# PIC32MK0512GPL100 register map
Vendor: Microchip
Registers are 32-bit, read-write, no defined reset value unless marked. A register's access mark holds for its fields unless they carry their own. Addresses are absolute, and some are shared; only a register's first bit layout is shown; [hi:lo] are bit positions; {n}, {i} and the like mark numbered series.

## PORTB
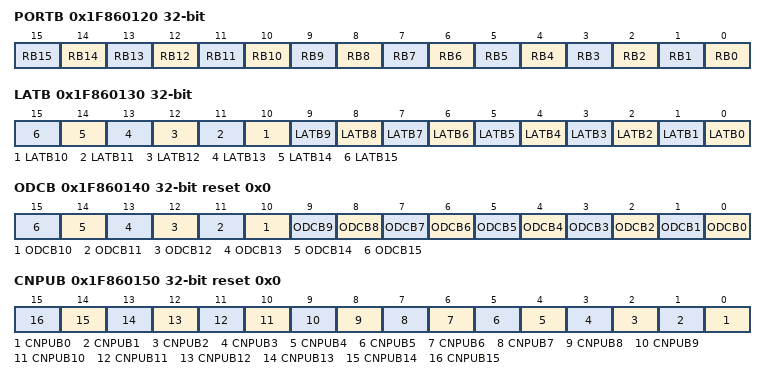
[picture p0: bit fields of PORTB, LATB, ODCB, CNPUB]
0x1F860120 PORTB — (power-on value ----------------xxxxxxxxxxxxxxxx)
  [n] RB{n} (n=0..15)
0x1F860130 LATB — (power-on value ----------------xxxxxxxxxxxxxxxx)
  [n] LATB{n} (n=0..15)
0x1F860140 ODCB reset 0x0
  [n] ODCB{n} (n=0..15)
0x1F860150 CNPUB reset 0x0
  [n] CNPUB{n} (n=0..15)
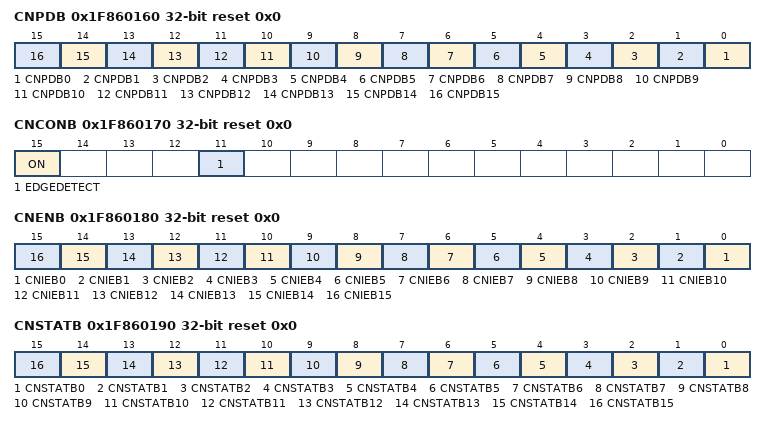
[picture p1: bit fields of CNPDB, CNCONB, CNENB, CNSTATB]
0x1F860160 CNPDB reset 0x0
  [n] CNPDB{n} (n=0..15)
0x1F860170 CNCONB reset 0x0
  [15] ON, [11] EDGEDETECT
0x1F860180 CNENB reset 0x0
  [n] CNIEB{n} (n=0..15)
0x1F860190 CNSTATB reset 0x0
  [n] CNSTATB{n} (n=0..15)
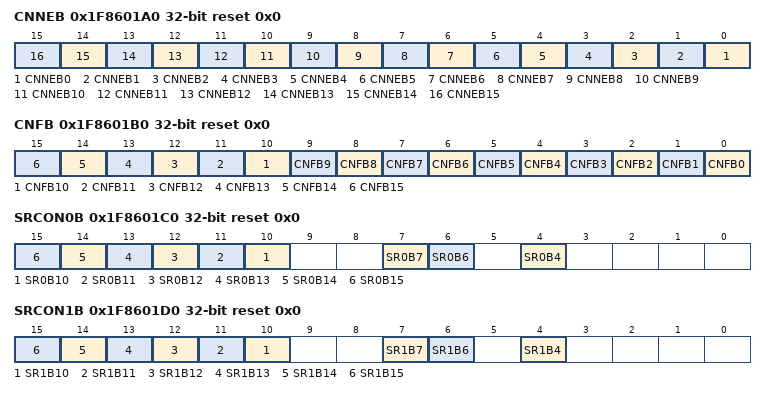
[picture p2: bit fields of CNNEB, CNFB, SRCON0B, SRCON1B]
0x1F8601A0 CNNEB reset 0x0
  [n] CNNEB{n} (n=0..15)
0x1F8601B0 CNFB reset 0x0
  [n] CNFB{n} (n=0..15)
0x1F8601C0 SRCON0B reset 0x0
  [n] SR0B{n} (n=10..15), [7] SR0B7, [6] SR0B6, [4] SR0B4
0x1F8601D0 SRCON1B reset 0x0
  [n] SR1B{n} (n=10..15), [7] SR1B7, [6] SR1B6, [4] SR1B4

## PORTC
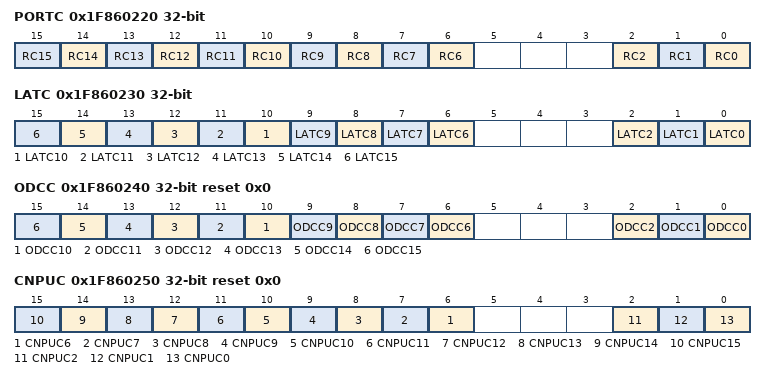
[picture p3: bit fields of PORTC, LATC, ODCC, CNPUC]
0x1F860220 PORTC — (power-on value ----------------xxxxxxxxxx---xxx)
  [n] RC{n} (n=6..15), [2] RC2, [1] RC1, [0] RC0
0x1F860230 LATC — (power-on value ----------------xxxxxxxxxx---xxx)
  [n] LATC{n} (n=6..15), [2] LATC2, [1] LATC1, [0] LATC0
0x1F860240 ODCC reset 0x0
  [n] ODCC{n} (n=6..15), [2] ODCC2, [1] ODCC1, [0] ODCC0
0x1F860250 CNPUC reset 0x0
  [n] CNPUC{n} (n=6..15), [2] CNPUC2, [1] CNPUC1, [0] CNPUC0
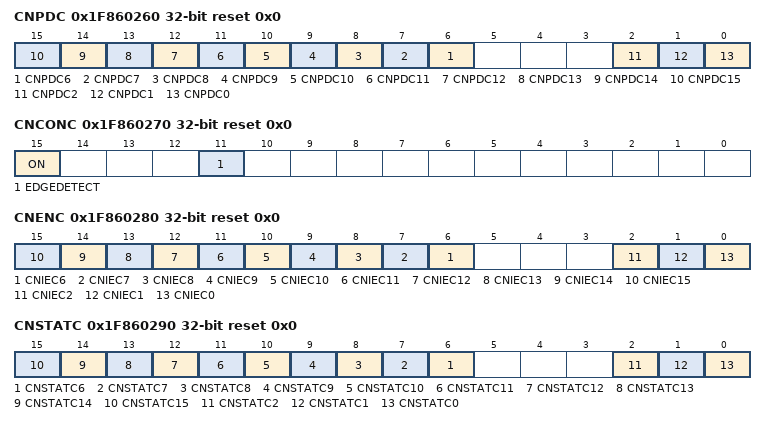
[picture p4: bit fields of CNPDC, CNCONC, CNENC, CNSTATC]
0x1F860260 CNPDC reset 0x0
  [n] CNPDC{n} (n=6..15), [2] CNPDC2, [1] CNPDC1, [0] CNPDC0
0x1F860270 CNCONC reset 0x0
  [15] ON, [11] EDGEDETECT
0x1F860280 CNENC reset 0x0
  [n] CNIEC{n} (n=6..15), [2] CNIEC2, [1] CNIEC1, [0] CNIEC0
0x1F860290 CNSTATC reset 0x0
  [n] CNSTATC{n} (n=6..15), [2] CNSTATC2, [1] CNSTATC1, [0] CNSTATC0
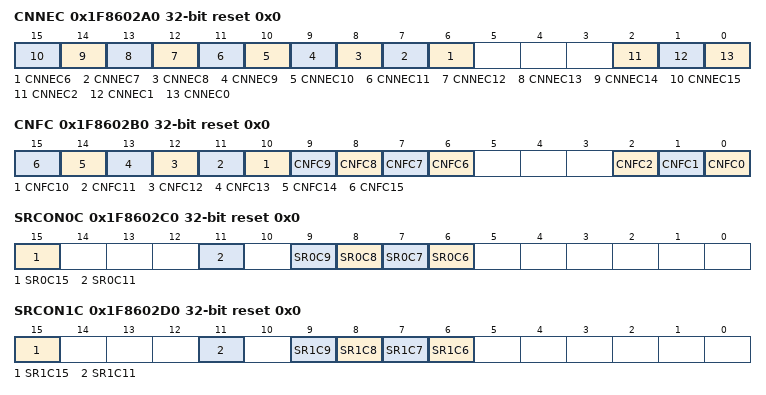
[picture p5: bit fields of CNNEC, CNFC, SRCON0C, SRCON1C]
0x1F8602A0 CNNEC reset 0x0
  [n] CNNEC{n} (n=6..15), [2] CNNEC2, [1] CNNEC1, [0] CNNEC0
0x1F8602B0 CNFC reset 0x0
  [n] CNFC{n} (n=6..15), [2] CNFC2, [1] CNFC1, [0] CNFC0
0x1F8602C0 SRCON0C reset 0x0
  [15] SR0C15, [11] SR0C11, [n] SR0C{n} (n=6..9)
0x1F8602D0 SRCON1C reset 0x0
  [15] SR1C15, [11] SR1C11, [n] SR1C{n} (n=6..9)

## PORTD
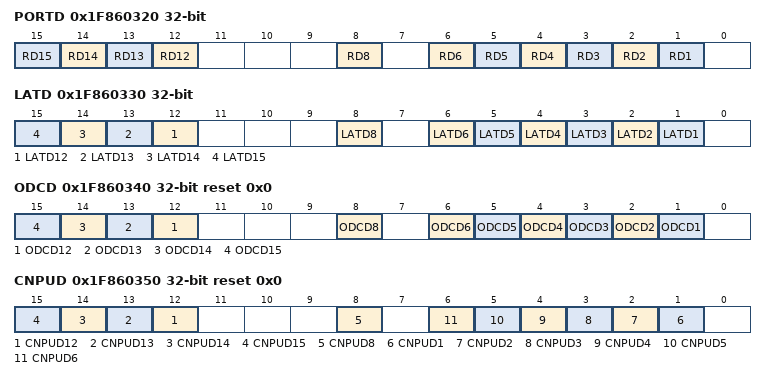
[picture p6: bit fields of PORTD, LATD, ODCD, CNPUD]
0x1F860320 PORTD — (power-on value ----------------xxxx---x-xxxxxx-)
  [n] RD{n} (n=12..15), [8] RD8, [n] RD{n} (n=1..6)
0x1F860330 LATD — (power-on value ----------------xxxx---x-xxxxxx-)
  [n] LATD{n} (n=12..15), [8] LATD8, [n] LATD{n} (n=1..6)
0x1F860340 ODCD reset 0x0
  [n] ODCD{n} (n=12..15), [8] ODCD8, [n] ODCD{n} (n=1..6)
0x1F860350 CNPUD reset 0x0
  [n] CNPUD{n} (n=12..15), [8] CNPUD8, [n] CNPUD{n} (n=1..6)
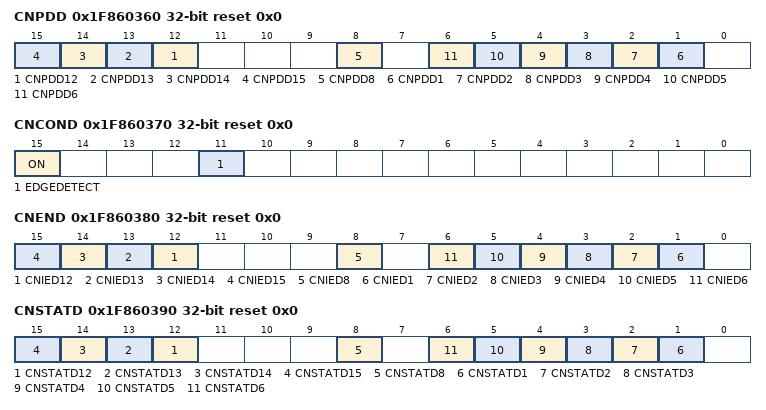
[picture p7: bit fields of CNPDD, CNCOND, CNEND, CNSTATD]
0x1F860360 CNPDD reset 0x0
  [n] CNPDD{n} (n=12..15), [8] CNPDD8, [n] CNPDD{n} (n=1..6)
0x1F860370 CNCOND reset 0x0
  [15] ON, [11] EDGEDETECT
0x1F860380 CNEND reset 0x0
  [n] CNIED{n} (n=12..15), [8] CNIED8, [n] CNIED{n} (n=1..6)
0x1F860390 CNSTATD reset 0x0
  [n] CNSTATD{n} (n=12..15), [8] CNSTATD8, [n] CNSTATD{n} (n=1..6)
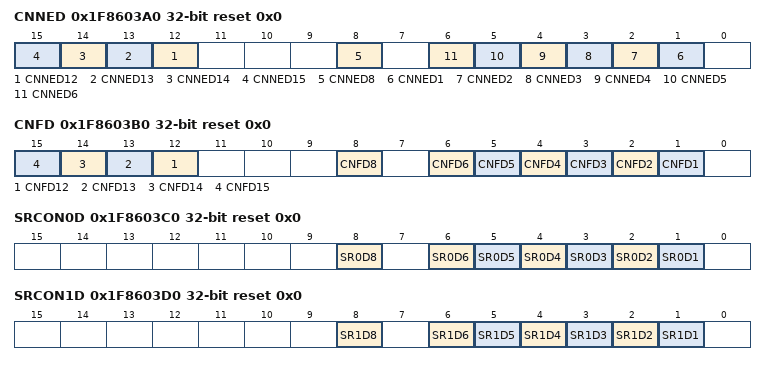
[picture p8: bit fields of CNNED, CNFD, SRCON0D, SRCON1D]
0x1F8603A0 CNNED reset 0x0
  [n] CNNED{n} (n=12..15), [8] CNNED8, [n] CNNED{n} (n=1..6)
0x1F8603B0 CNFD reset 0x0
  [n] CNFD{n} (n=12..15), [8] CNFD8, [n] CNFD{n} (n=1..6)
0x1F8603C0 SRCON0D reset 0x0
  [8] SR0D8, [n] SR0D{n} (n=1..6)
0x1F8603D0 SRCON1D reset 0x0
  [8] SR1D8, [n] SR1D{n} (n=1..6)

## PORTE
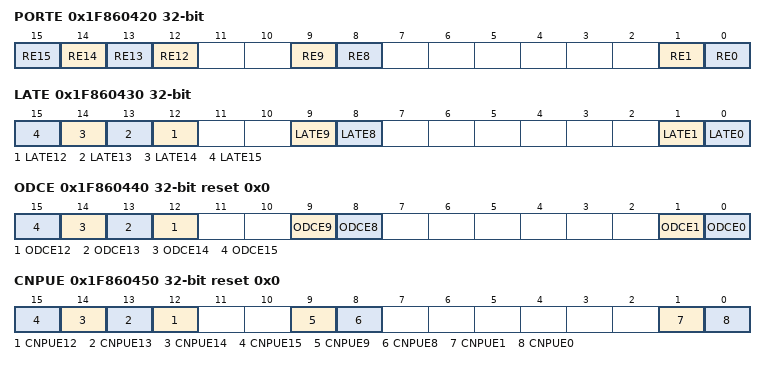
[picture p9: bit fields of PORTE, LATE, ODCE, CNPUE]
0x1F860420 PORTE — (power-on value ----------------xxxx--xx------xx)
  [n] RE{n} (n=12..15), [9] RE9, [8] RE8, [1] RE1, [0] RE0
0x1F860430 LATE — (power-on value ----------------xxxx--xx------xx)
  [n] LATE{n} (n=12..15), [9] LATE9, [8] LATE8, [1] LATE1, [0] LATE0
0x1F860440 ODCE reset 0x0
  [n] ODCE{n} (n=12..15), [9] ODCE9, [8] ODCE8, [1] ODCE1, [0] ODCE0
0x1F860450 CNPUE reset 0x0
  [n] CNPUE{n} (n=12..15), [9] CNPUE9, [8] CNPUE8, [1] CNPUE1, [0] CNPUE0
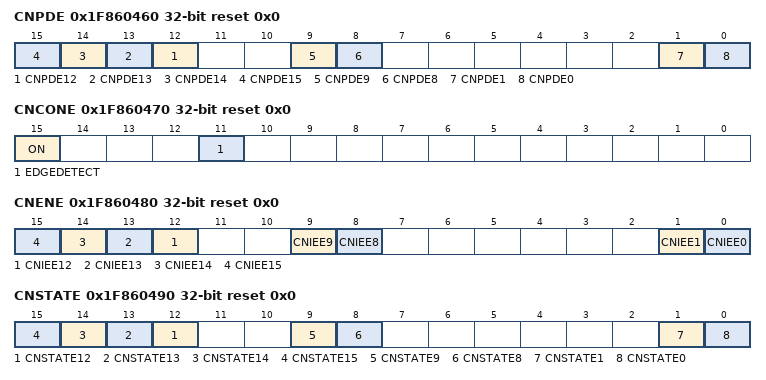
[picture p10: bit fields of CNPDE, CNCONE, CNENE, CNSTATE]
0x1F860460 CNPDE reset 0x0
  [n] CNPDE{n} (n=12..15), [9] CNPDE9, [8] CNPDE8, [1] CNPDE1, [0] CNPDE0
0x1F860470 CNCONE reset 0x0
  [15] ON, [11] EDGEDETECT
0x1F860480 CNENE reset 0x0
  [n] CNIEE{n} (n=12..15), [9] CNIEE9, [8] CNIEE8, [1] CNIEE1, [0] CNIEE0
0x1F860490 CNSTATE reset 0x0
  [n] CNSTATE{n} (n=12..15), [9] CNSTATE9, [8] CNSTATE8, [1] CNSTATE1, [0] CNSTATE0
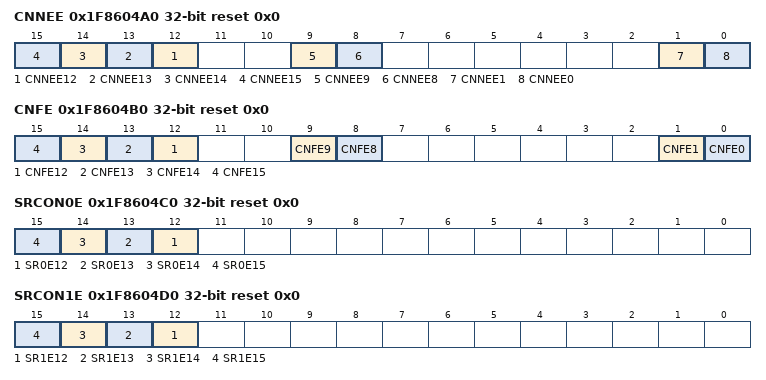
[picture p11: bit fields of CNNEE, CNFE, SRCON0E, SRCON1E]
0x1F8604A0 CNNEE reset 0x0
  [n] CNNEE{n} (n=12..15), [9] CNNEE9, [8] CNNEE8, [1] CNNEE1, [0] CNNEE0
0x1F8604B0 CNFE reset 0x0
  [n] CNFE{n} (n=12..15), [9] CNFE9, [8] CNFE8, [1] CNFE1, [0] CNFE0
0x1F8604C0 SRCON0E reset 0x0
  [n] SR0E{n} (n=12..15)
0x1F8604D0 SRCON1E reset 0x0
  [n] SR1E{n} (n=12..15)
